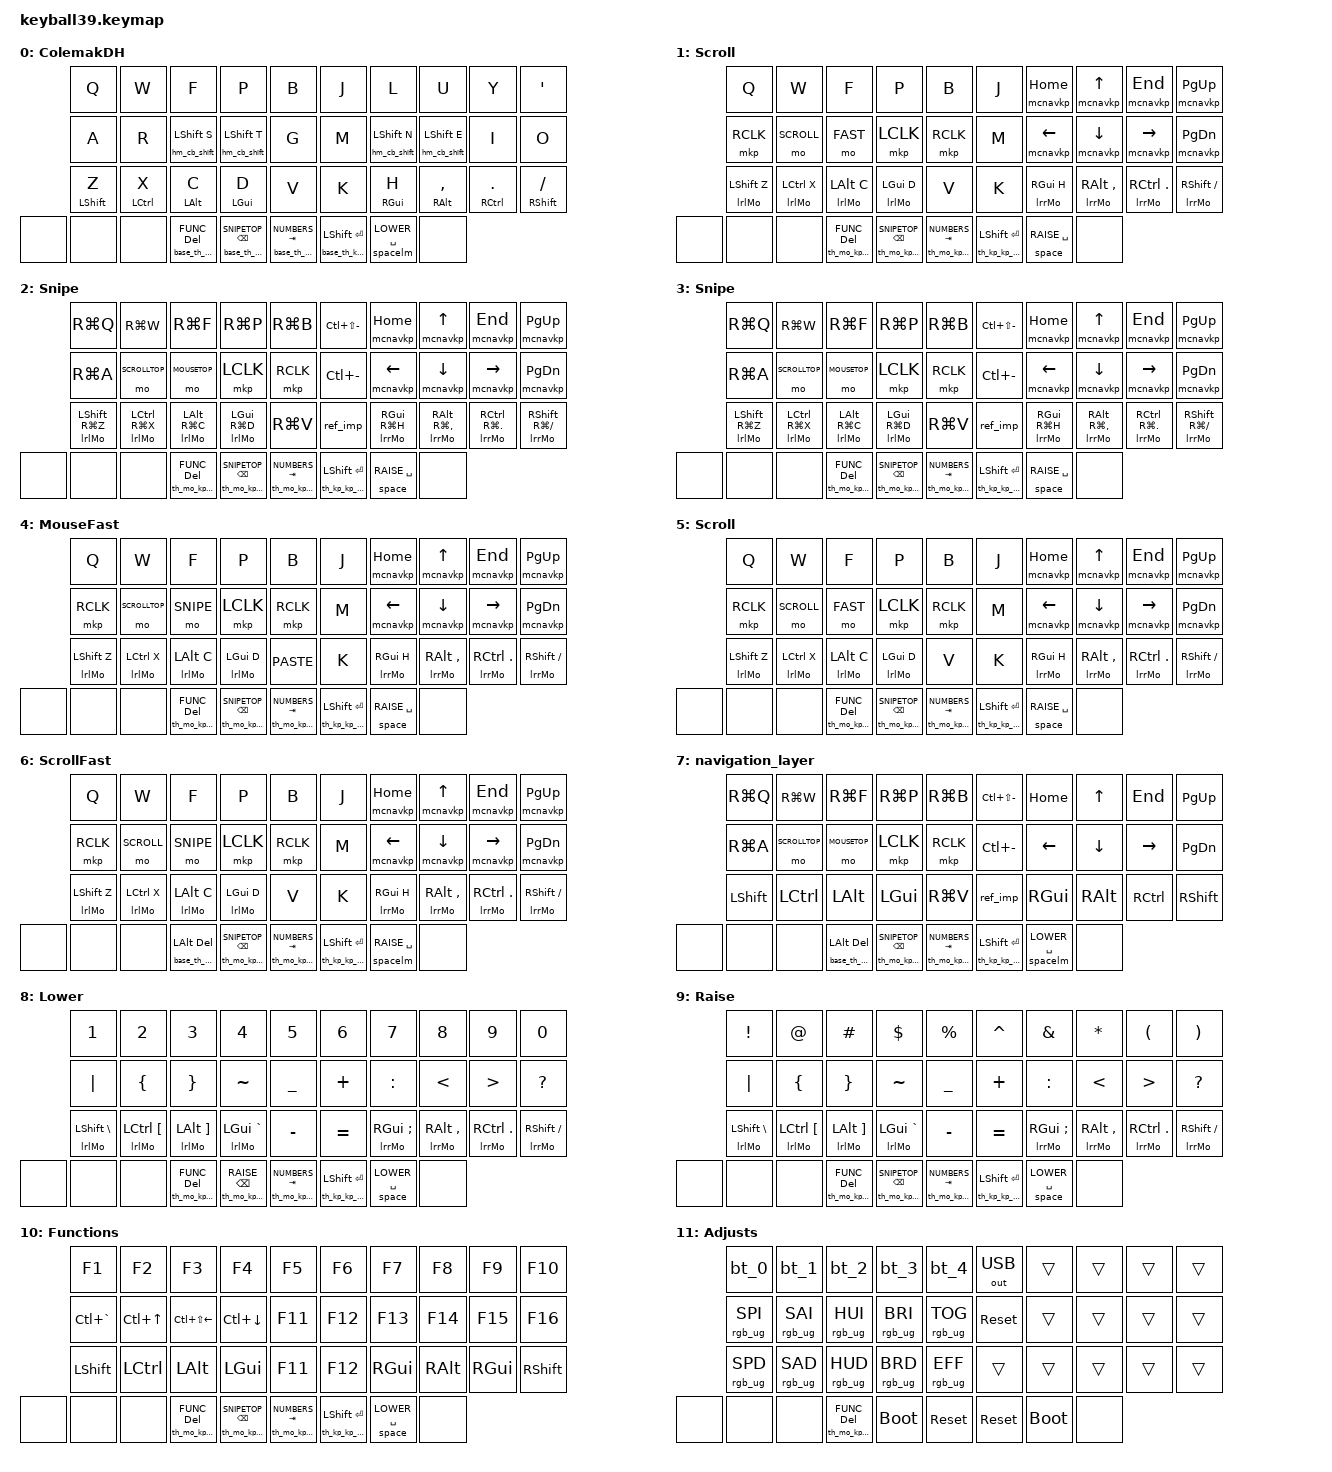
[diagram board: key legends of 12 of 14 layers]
// git add . && git commit -m 'home rows' && git push


/*
cd /Users/haroldhernandez/keyball39/zmk-config-Keyball39
source ~/zephyrproject/.venv/bin/activate

//To install local zmk
# Tell west the config directory included in this repo
west init -l config
west update                # fetch Zephyr, ZMK, HALs
west zephyr-export         # sets Zephyr CMake package files in venv



west build -p \
  -s zmk/app -b nice_nano_v2 -d build/right \
  -S zmk-usb-logging \
  -S studio-rpc-usb-uart \
  -- \
  -DZMK_CONFIG="${PWD}/config" \
  -DOVERLAY_CONFIG=${PWD}/config/debug.conf \
  -DSHIELD=keyball39_right



west build -p \
  -s zmk/app -b nice_nano_v2 -d build/left \
  -S zmk-usb-logging \
  -- \
  -DZMK_CONFIG="${PWD}/config" \
  -DOVERLAY_CONFIG=${PWD}/config/debug.conf \
  -DSHIELD=keyball39_left

#To check the numbers:

   ls /dev/tty.usbmodem*   # data-terminal devices
   ls /dev/cu.usbmodem*    # call-up devices (identical, no HW flow-ctrl)

#and run to actuvate debug 
   sudo tio /dev/tty.usbmodem2101
   
-------------------------------------------------

west build -p \
  -s zmk/app -b nice_nano_v2 -d build/left \
  -- \
  -DZMK_CONFIG="${PWD}/config" \
  -DOVERLAY_CONFIG=${PWD}/config/debug.conf \
  -DSHIELD=keyball39_left

west build -p \
  -s zmk/app -b nice_nano_v2 -d build/right \
  -- \
  -DZMK_CONFIG="${PWD}/config" \
  -DOVERLAY_CONFIG=${PWD}/config/debug.conf \
  -DSHIELD=keyball39_right

*/





/* On demand includes */

#include <behaviors/mouse_keys.dtsi>
#include <dt-bindings/zmk/mouse.h>
#include <behaviors.dtsi>
#include <dt-bindings/zmk/bt.h>
#include <dt-bindings/zmk/keys.h>
#include <dt-bindings/zmk/rgb.h>
#include <dt-bindings/zmk/outputs.h>
#include <dt-bindings/zmk/pointing.h>
//#include <input/processors.dtsi>


//     0  1  2  3  4         5  6  7  8  9
//    10 11 12 13 14        15 16 17 18 19
//    20 21 22 23 24        25 26 27 28 29 
//    30 31 32 33 34 35  36 37          38

//     0  1  2  3  4     5  6  7  8  9
//    10 11 12 13 14    15 16 17 18 19
//20  21 22 23 24 25    26 27 28 29 30  31
//        32 33 34         35 36 37


&lt {
    tapping-term-ms = <240>;
    flavor = "balanced";
    quick-tap-ms = <150>;
};

&mt {
    tapping-term-ms = <200>;
    flavor = "tap-preferred";
    quick-tap-ms = <150>;
};

&sl {
    release-after-ms = <4000>;
};


&caps_word { continue-list = <UNDERSCORE MINUS BACKSPACE>; };
#include "mouse.dtsi"

/ {

    #include "macros/macros_general.dtsi"
    #include "behaviors/behaviors_general.dtsi"
    #include "combos/combos_general.dtsi"

    keymap {
        compatible = "zmk,keymap";
        base_layer {
            label = "ColemakDH";
            bindings = <
                               &kp Q                  &kp W               &kp F                             &kp P                           &kp B                             &kp J    &kp L                            &kp U                               &kp Y                &kp SQT
                               &kp A                  &kp R               &hm_cb_shift LSHFT S              &hm_cb_shift LSHFT T            &kp G                             &kp M    &hm_cb_shift LSHFT N             &hm_cb_shift LSHFT E                &kp I                &kp O
                               &hml_hr LSHFT Z        &hml_hr LCTRL X     &hml_hr LALT C                    &hml_hr LGUI D                  &kp V                             &kp K    &hmr_hr RGUI H                   &hmr_hr RALT COMMA                  &hmr_hr RCTRL DOT    &hmr_hr RSHFT SLASH        
&none &none  &none &base_th_mo_kp_hp FUNC DEL  &base_th_mo_kp_hp SNIPETOP BACKSPACE  &base_th_mo_kp_hp NUMBERS TAB                 &base_th_kp_kp_hp LSHFT ENTER  &spacelm LOWER SPACE   &none
            >;
        };

         scroll_layer {
            label = "Scroll";
            bindings = <
&kp Q                      &kp W                    &kp F                &kp P                 &kp B                                 &kp J           &mcnavkp HOME              &mcnavkp UP                    &mcnavkp END                    &mcnavkp PG_UP
&mkp RCLK                  &mo SCROLL               &mo FAST             &mkp LCLK             &mkp RCLK                             &kp M           &mcnavkp LEFT              &mcnavkp DOWN                  &mcnavkp RIGHT                  &mcnavkp PG_DN
&lrlMo LSHFT Z            &lrlMo LCTRL X          &lrlMo LALT C       &lrlMo LGUI D        &kp V                                 &kp K           &lrrMo RGUI H              &lrrMo RALT COMMA              &lrrMo RCTRL DOT                &lrrMo RSHFT SLASH 
 &none &none  &none &th_mo_kp_hp FUNC DEL  &th_mo_kp_hp SNIPETOP BACKSPACE  &th_mo_kp_hp NUMBERS TAB                  &th_kp_kp_hp LSHFT ENTER   &space RAISE SPACE    &none
            >;
        };

        snipe_layer {
            label = "Snipe";
            bindings = <
&kp RG(Q)                  &kp RG(W)                   &kp RG(F)             &kp RG(P)             &kp RG(B)                             &kp LC(LS(MINUS))           &mcnavkp HOME              &mcnavkp UP                    &mcnavkp END                    &mcnavkp PG_UP
&kp RG(A)                  &mo SCROLLTOP               &mo MOUSETOP          &mkp LCLK             &mkp RCLK                             &kp LC(MINUS)               &mcnavkp LEFT              &mcnavkp DOWN                  &mcnavkp RIGHT                  &mcnavkp PG_DN
&lrlMo LSHFT RG(Z)        &lrlMo LCTRL RG(X)         &lrlMo LALT RG(C)    &lrlMo LGUI RG(D)    &kp RG(V)                             &ref_imp                    &lrrMo RGUI RG(H)          &lrrMo RALT RG(COMMA)          &lrrMo RCTRL RG(DOT)            &lrrMo RSHFT RG(SLASH) 
 &none &none  &none &th_mo_kp_hp FUNC DEL  &th_mo_kp_hp SNIPETOP BACKSPACE  &th_mo_kp_hp NUMBERS TAB                  &th_kp_kp_hp LSHFT ENTER   &space RAISE SPACE    &none
            >;
        };

        snipetop_layer {
            label = "Snipe";
            bindings = <
&kp RG(Q)                  &kp RG(W)                   &kp RG(F)             &kp RG(P)             &kp RG(B)                             &kp LC(LS(MINUS))           &mcnavkp HOME              &mcnavkp UP                    &mcnavkp END                    &mcnavkp PG_UP
&kp RG(A)                  &mo SCROLLTOP               &mo MOUSETOP          &mkp LCLK             &mkp RCLK                             &kp LC(MINUS)               &mcnavkp LEFT              &mcnavkp DOWN                  &mcnavkp RIGHT                  &mcnavkp PG_DN
&lrlMo LSHFT RG(Z)        &lrlMo LCTRL RG(X)         &lrlMo LALT RG(C)    &lrlMo LGUI RG(D)    &kp RG(V)                             &ref_imp                    &lrrMo RGUI RG(H)          &lrrMo RALT RG(COMMA)          &lrrMo RCTRL RG(DOT)            &lrrMo RSHFT RG(SLASH) 
&none &none  &none  &th_mo_kp_hp FUNC DEL  &th_mo_kp_hp SNIPETOP BACKSPACE  &th_mo_kp_hp NUMBERS TAB                  &th_kp_kp_hp LSHFT ENTER   &space RAISE SPACE    &none
            >;
        };

        mousetop_layer {
            label = "MouseFast";
            bindings = <
&kp Q                      &kp W                    &kp F                 &kp P                 &kp B                                   &kp J          &mcnavkp HOME              &mcnavkp UP                    &mcnavkp END                    &mcnavkp PG_UP
&mkp RCLK                  &mo SCROLLTOP            &mo SNIPE             &mkp LCLK             &mkp RCLK                               &kp M          &mcnavkp LEFT              &mcnavkp DOWN                  &mcnavkp RIGHT                  &mcnavkp PG_DN
&lrlMo LSHFT Z            &lrlMo LCTRL X          &lrlMo LALT C        &lrlMo LGUI D        &kp K_PASTE                             &kp K          &lrrMo RGUI H              &lrrMo RALT COMMA              &lrrMo RCTRL DOT                &lrrMo RSHFT SLASH 
&none &none  &none &th_mo_kp_hp FUNC DEL  &th_mo_kp_hp SNIPETOP BACKSPACE  &th_mo_kp_hp NUMBERS TAB                        &th_kp_kp_hp LSHFT ENTER   &space RAISE SPACE   &none 
            >;
        };

        scrolltop_layer {
            label = "Scroll";
            bindings = <
&kp Q                      &kp W                    &kp F                &kp P                 &kp B                                 &kp J               &mcnavkp HOME              &mcnavkp UP                    &mcnavkp END                    &mcnavkp PG_UP
&mkp RCLK                  &mo SCROLL               &mo FAST             &mkp LCLK             &mkp RCLK                             &kp M               &mcnavkp LEFT              &mcnavkp DOWN                  &mcnavkp RIGHT                  &mcnavkp PG_DN
&lrlMo LSHFT Z            &lrlMo LCTRL X          &lrlMo LALT C       &lrlMo LGUI D        &kp V                                 &kp K               &lrrMo RGUI H              &lrrMo RALT COMMA              &lrrMo RCTRL DOT                &lrrMo RSHFT SLASH 
&none &none  &none &th_mo_kp_hp FUNC DEL  &th_mo_kp_hp SNIPETOP BACKSPACE  &th_mo_kp_hp NUMBERS TAB                  &th_kp_kp_hp LSHFT ENTER   &space RAISE SPACE    &none
            >;
        };

    fast_layer {
        label = "ScrollFast";
        bindings = <
&kp Q                      &kp W                    &kp F                  &kp P                  &kp B                                 &kp J               &mcnavkp HOME              &mcnavkp UP                    &mcnavkp END                    &mcnavkp PG_UP
&mkp RCLK                  &mo SCROLL               &mo SNIPE              &mkp LCLK              &mkp RCLK                             &kp M               &mcnavkp LEFT              &mcnavkp DOWN                  &mcnavkp RIGHT                  &mcnavkp PG_DN
&lrlMo LSHFT Z            &lrlMo LCTRL X          &lrlMo LALT C         &lrlMo LGUI D         &kp V                                 &kp K               &lrrMo RGUI H              &lrrMo RALT COMMA              &lrrMo RCTRL DOT                &lrrMo RSHFT SLASH 
&none &none  &none &base_th_mo_kp_hp LALT DEL  &th_mo_kp_hp SNIPETOP BACKSPACE  &th_mo_kp_hp NUMBERS TAB                    &th_kp_kp_hp LSHFT ENTER  &spacelm RAISE SPACE   &none
        >;
    };

    navigation_layer {
            bindings = <
&kp RG(Q)                  &kp RG(W)                   &kp RG(F)             &kp RG(P)             &kp RG(B)                             &kp LC(LS(MINUS))           &kp HOME                   &kp UP                         &kp END                         &kp PG_UP
&kp RG(A)                  &mo SCROLLTOP               &mo MOUSETOP          &mkp LCLK             &mkp RCLK                             &kp LC(MINUS)               &kp LEFT                   &kp DOWN                       &kp RIGHT                       &kp PG_DN
&kp LSHFT                  &kp LCTRL                   &kp LALT              &kp LGUI              &kp RG(V)                             &ref_imp                    &kp RGUI                   &kp RALT                       &kp RCTRL                       &kp RSHFT  
&none &none  &none &base_th_mo_kp_hp LALT DEL  &th_mo_kp_hp SNIPETOP BACKSPACE  &th_mo_kp_hp NUMBERS TAB                    &th_kp_kp_hp LSHFT ENTER  &spacelm LOWER SPACE   &none
            >;
        };

        lower_layer {
            label = "Lower";
            bindings = <
                  &kp N1                         &kp N2                        &kp N3                        &kp N4              &kp N5                                    &kp N6             &kp N7                    &kp N8                   &kp N9                 &kp N0
                  &kp PIPE                       &kp LBRC                      &kp RBRC                      &kp TILDE           &kp UNDER                                 &kp PLUS           &kp COLON                 &kp LT                   &kp GT                 &kp QUESTION
                  &lrlMo LSHFT BSLH              &lrlMo LCTRL LBKT             &lrlMo LALT RBKT              &lrlMo LGUI GRAVE   &kp MINUS                                 &kp EQUAL          &lrrMo RGUI SEMI          &lrrMo RALT COMMA        &lrrMo RCTRL DOT       &lrrMo RSHFT SLASH 
 &none &none  &none &th_mo_kp_hp FUNC DEL  &th_mo_kp_hp RAISE BACKSPACE  &th_mo_kp_hp NUMBERS TAB                  &th_kp_kp_hp LSHFT ENTER   &space LOWER SPACE    &none
            >;
        };

        raise_layer {
            label = "Raise";
            bindings = <
                  &kp EXCL                   &kp AT                      &kp HASH                         &kp DLLR                          &kp PRCNT                             &kp CARET           &kp AMPS                   &kp STAR                  &kp LPAR                  &kp RPAR
                  &kp PIPE                   &kp LBRC                    &kp RBRC                         &kp TILDE                         &kp UNDER                             &kp PLUS            &kp COLON                  &kp LT                   &kp GT                     &kp QUESTION
                  &lrlMo LSHFT BSLH          &lrlMo LCTRL LBKT           &lrlMo LALT RBKT                 &lrlMo LGUI GRAVE                 &kp MINUS                             &kp EQUAL           &lrrMo RGUI SEMI           &lrrMo RALT COMMA         &lrrMo RCTRL DOT          &lrrMo RSHFT SLASH              
 &none &none  &none &th_mo_kp_hp FUNC DEL  &th_mo_kp_hp SNIPETOP BACKSPACE  &th_mo_kp_hp NUMBERS TAB                  &th_kp_kp_hp LSHFT ENTER   &space LOWER SPACE   &none
            >;
        };

        layer_func {
            label = "Functions";
            bindings = <
        &kp F1          &kp F2         &kp F3                &kp F4           &kp F5                              &kp F6             &kp F7              &kp F8            &kp F9            &kp F10
        &kp LC(GRAVE)   &kp LC(UP)     &kp LC(LS(LEFT))      &kp LC(DOWN)     &kp F11                             &kp F12            &kp F13             &kp F14           &kp F15           &kp F16 
        &kp LSHFT       &kp LCTRL      &kp LALT              &kp LGUI         &kp F11                             &kp F12            &kp RGUI            &kp RALT          &kp RGUI          &kp RSHFT      
&none &none  &none  &th_mo_kp_hp FUNC DEL  &th_mo_kp_hp SNIPETOP BACKSPACE  &th_mo_kp_hp NUMBERS TAB                  &th_kp_kp_hp LSHFT ENTER   &space LOWER SPACE   &none
            >;
        };

        adjust_layer {
            label = "Adjusts";
            bindings = <
            &bt_0               &bt_1               &bt_2               &bt_3               &bt_4                                       &out OUT_USB            &trans                    &trans                    &trans           &trans
            &rgb_ug RGB_SPI     &rgb_ug RGB_SAI     &rgb_ug RGB_HUI     &rgb_ug RGB_BRI     &rgb_ug RGB_TOG                             &sys_reset              &trans                    &trans                    &trans           &trans
            &rgb_ug RGB_SPD     &rgb_ug RGB_SAD     &rgb_ug RGB_HUD     &rgb_ug RGB_BRD     &rgb_ug RGB_EFF                             &trans                  &trans                    &trans                    &trans           &trans
&none &none  &none  &th_mo_kp_hp FUNC DEL   &bootloader   &sys_reset                                                &sys_reset   &bootloader  &none
            >;
        };

        layer_numbers {
            label = "Numbers";
            bindings = <
                  &kp EXCL                   &kp AT                      &kp HASH                         &kp DLLR                          &kp PRCNT                             &kp DOT            &kp N7                    &kp N8                   &kp N9           &kp N0
                  &kp PIPE                   &kp LBRC                    &kp RBRC                         &kp TILDE                         &kp COMMA                             &kp EQUAL          &kp N4                    &kp N5                   &kp N6           &kp STAR
                  &lrlMo LSHFT BSLH          &lrlMo LCTRL LBKT           &lrlMo LALT RBKT                 &lrlMo LGUI GRAVE                 &kp MINUS                             &kp PLUS           &kp N1                    &kp N2                   &kp N3           &kp SLASH        
 &none &none  &none &th_mo_kp_hp FUNC DEL  &th_mo_kp_hp SNIPETOP BACKSPACE  &th_mo_kp_hp NUMBERS TAB                  &th_kp_kp_hp LSHFT ENTER   &space LOWER SPACE   &none
            >;
        };

        layer_system {
            label = "System";
            bindings = <
&kp C_BRI_DN           &kp C_BRI_UP               &none                         &none              &none                             &kp C_VOL_UP     &kp C_PREV         &kp C_PP           &kp C_NEXT      &mc_lock_screen
&bt_0                  &bt_1                      &bt_2                         &bt_3              &out OUT_USB                      &kp C_VOL_DN     &bt_0              &bt_1              &bt_2           &out OUT_USB
&kp LSHFT              &kp LCTRL                  &kp LALT                      &kp LGUI           &none                             &kp C_MUTE       &kp RGUI           &kp RALT           &kp RCTRL       &kp RSHFT
 &none &none  &none &th_mo_kp_hp FUNC DEL  &th_mo_kp_hp SNIPETOP BACKSPACE  &th_mo_kp_hp NUMBERS TAB                  &th_kp_kp_hp LSHFT ENTER   &space LOWER SPACE   &none
            >;
        };


    };

};

